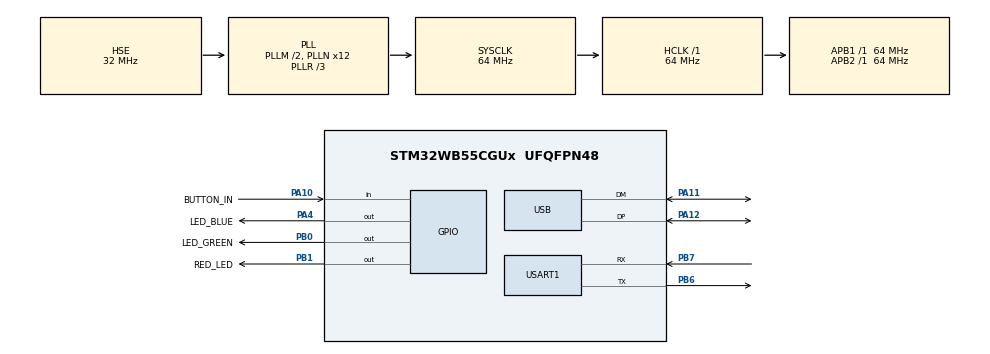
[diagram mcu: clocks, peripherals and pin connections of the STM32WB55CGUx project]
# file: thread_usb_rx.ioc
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Dma.Request0=USART1_RX
Dma.Request1=USART1_TX
Dma.USART1_RX.0.Direction=DMA_PERIPH_TO_MEMORY
Dma.USART1_RX.0.EventEnable=DISABLE
Dma.USART1_RX.0.Instance=DMA1_Channel1
Dma.USART1_RX.0.MemDataAlignment=DMA_MDATAALIGN_BYTE
Dma.USART1_RX.0.MemInc=DMA_MINC_ENABLE
Dma.USART1_RX.0.Mode=DMA_NORMAL
Dma.USART1_RX.0.PeriphDataAlignment=DMA_PDATAALIGN_BYTE
Dma.USART1_RX.0.PeriphInc=DMA_PINC_DISABLE
Dma.USART1_RX.0.Polarity=HAL_DMAMUX_REQ_GEN_RISING
Dma.USART1_RX.0.Priority=DMA_PRIORITY_LOW
Dma.USART1_RX.0.RequestNumber=1
Dma.USART1_RX.0.SignalID=NONE
Dma.USART1_RX.0.SyncEnable=DISABLE
Dma.USART1_RX.0.SyncPolarity=HAL_DMAMUX_SYNC_NO_EVENT
Dma.USART1_RX.0.SyncRequestNumber=1
Dma.USART1_RX.0.SyncSignalID=NONE
Dma.USART1_TX.1.Direction=DMA_MEMORY_TO_PERIPH
Dma.USART1_TX.1.EventEnable=DISABLE
Dma.USART1_TX.1.Instance=DMA1_Channel2
Dma.USART1_TX.1.MemDataAlignment=DMA_MDATAALIGN_BYTE
Dma.USART1_TX.1.MemInc=DMA_MINC_ENABLE
Dma.USART1_TX.1.Mode=DMA_NORMAL
Dma.USART1_TX.1.PeriphDataAlignment=DMA_PDATAALIGN_BYTE
Dma.USART1_TX.1.PeriphInc=DMA_PINC_DISABLE
Dma.USART1_TX.1.Polarity=HAL_DMAMUX_REQ_GEN_RISING
Dma.USART1_TX.1.Priority=DMA_PRIORITY_LOW
Dma.USART1_TX.1.RequestNumber=1
Dma.USART1_TX.1.SignalID=NONE
Dma.USART1_TX.1.SyncEnable=DISABLE
Dma.USART1_TX.1.SyncPolarity=HAL_DMAMUX_SYNC_NO_EVENT
Dma.USART1_TX.1.SyncRequestNumber=1
Dma.USART1_TX.1.SyncSignalID=NONE
Mcu.Family=STM32WB
Mcu.Name=STM32WB55CGUx
Mcu.Package=UFQFPN48
NVIC.DMA1_Channel1_IRQn=true\:0\:0\:false\:false\:true\:false\:true\:true
NVIC.DMA1_Channel2_IRQn=true\:0\:0\:false\:false\:true\:false\:true\:true
NVIC.HSEM_IRQn=true\:0\:0\:false\:false\:true\:false\:true\:true
NVIC.IPCC_C1_RX_IRQn=true\:0\:0\:false\:false\:true\:true\:true\:true
NVIC.IPCC_C1_TX_IRQn=true\:0\:0\:false\:false\:true\:true\:true\:true
NVIC.PriorityGroup=NVIC_PRIORITYGROUP_4
NVIC.USART1_IRQn=true\:0\:0\:false\:false\:true\:true\:true\:true
NVIC.USB_HP_IRQn=true\:0\:0\:false\:false\:true\:true\:true\:true
NVIC.USB_LP_IRQn=true\:0\:0\:false\:false\:true\:true\:true\:true
OSC_IN.Mode=HSE-External-Oscillator
OSC_IN.Signal=RCC_OSC_IN
OSC_OUT.Mode=HSE-External-Oscillator
OSC_OUT.Signal=RCC_OSC_OUT
PA10.GPIO_Label=BUTTON_IN
PA10.Signal=GPIO_Input
PA11.Mode=Device
PA11.Signal=USB_DM
PA12.Mode=Device
PA12.Signal=USB_DP
PA13.Mode=Serial_Wire
PA13.Signal=SYS_JTMS-SWDIO
PA14.Mode=Serial_Wire
PA14.Signal=SYS_JTCK-SWCLK
PA4.GPIO_Label=LED_BLUE
PA4.Signal=GPIO_Output
PB0.GPIO_Label=LED_GREEN
PB0.Signal=GPIO_Output
PB1.GPIO_Label=RED_LED
PB1.Signal=GPIO_Output
PB6.Mode=Asynchronous
PB6.Signal=USART1_TX
PB7.Mode=Asynchronous
PB7.Signal=USART1_RX
PC14-OSC32_IN.Mode=LSE-External-Oscillator
PC14-OSC32_IN.Signal=RCC_OSC32_IN
PC15-OSC32_OUT.Mode=LSE-External-Oscillator
PC15-OSC32_OUT.Signal=RCC_OSC32_OUT
ProjectManager.HeapSize=0x2000
ProjectManager.StackSize=0xA00
ProjectManager.TargetToolchain=STM32CubeIDE
RCC.ADCFreq_Value=64000000
RCC.AHB2CLKDivider=RCC_SYSCLK_DIV2
RCC.AHBFreq_Value=64000000
RCC.APB1Freq_Value=64000000
RCC.APB1TimFreq_Value=64000000
RCC.APB2Freq_Value=64000000
RCC.APB2TimFreq_Value=64000000
RCC.APB3Freq_Value=16000000
RCC.CK48CLockSelection=RCC_USBCLKSOURCE_PLL
RCC.CortexFreq_Value=64000000
RCC.HCLKFreq_Value=64000000
RCC.HSE_VALUE=32000000
RCC.HSI48_VALUE=48000000
RCC.HSI_VALUE=16000000
RCC.PLLM=RCC_PLLM_DIV2
RCC.PLLN=12
RCC.PLLQ=RCC_PLLQ_DIV4
RCC.PLLR=RCC_PLLR_DIV3
RCC.PLLSourceVirtual=RCC_PLLSOURCE_HSE
RCC.RTCClockSelection=RCC_RTCCLKSOURCE_LSE
RCC.SYSCLKFreq_VALUE=64000000
RCC.SYSCLKSource=RCC_SYSCLKSOURCE_PLLCLK
RCC.USBFreq_Value=48000000
RCC.VCOOutputFreq_Value=192000000
RF1.Mode=RF1_Activate
RF1.Signal=RF_RF1
STM32_WPAN.CFG_CLI_UART=hw_uart1
STM32_WPAN.CFG_HW_USART1_ENABLED=1
USART1.VirtualMode-Asynchronous=VM_ASYNC
USB_DEVICE.CLASS_NAME_FS=CDC
USB_DEVICE.VirtualMode=Cdc
USB_DEVICE.VirtualModeFS=Cdc_FS
VP_HSEM_VS_HSEM.Mode=HSEM_Activate
VP_IPCC_VS_IPCC.Mode=IPCC_Activate
VP_RTC_VS_RTC_Activate.Mode=RTC_Enabled
VP_SEQUENCER_VS_SEQUENCER.Mode=SEQUENCER_Enabled
VP_STM32_WPAN_VS_THREAD.Mode=STM32_WPAN_Enabled
VP_TINY_LPM_VS_TINY_LPM.Mode=TINY_LPM_Enabled
VP_USB_DEVICE_VS_USB_DEVICE_CDC_FS.Mode=CDC_FS
board=custom

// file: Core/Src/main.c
/* USER CODE BEGIN Header */
/**
  ******************************************************************************
  * @file           : main.c
  * @brief          : Main program body
  ******************************************************************************
  * @attention
  *
  * Copyright (c) 2022 STMicroelectronics.
  * All rights reserved.
  *
  * This software is licensed under terms that can be found in the LICENSE file
  * in the root directory of this software component.
  * If no LICENSE file comes with this software, it is provided AS-IS.
  *
  ******************************************************************************
  */
/* USER CODE END Header */
#include "main.h"
#include "dma.h"
#include "ipcc.h"
#include "rf.h"
#include "rtc.h"
#include "usart.h"
#include "usb_device.h"
#include "gpio.h"

void SystemClock_Config(void);
void PeriphCommonClock_Config(void);

/* USER CODE BEGIN 0 */

#define PUTCHAR_PROTOTYPE int __io_putchar(int ch)

PUTCHAR_PROTOTYPE
{
  /* Place your implementation of fputc here */
  /* e.g. write a character to the USART1 and Loop until the end of transmission */
 // HAL_UART_Transmit(&huart1, (uint8_t *)&ch, 1, 0xFFFF);
	while(CDC_Transmit_FS((uint8_t *)&ch, 1) == 1);

  return ch;
}

/*
#define LED_BLUE_Pin GPIO_PIN_4
#define LED_BLUE_GPIO_Port GPIOA
#define LED_GREEN_Pin GPIO_PIN_0
#define LED_GREEN_GPIO_Port GPIOB
#define RED_LED_Pin GPIO_PIN_1
#define RED_LED_GPIO_Port GPIOB
#define BUTTON_IN_Pin GPIO_PIN_10
#define BUTTON_IN_GPIO_Port GPIOA
 */

/* USER CODE END 0 */

int main(void)
{

  /* MCU Configuration--------------------------------------------------------*/

  /* Reset of all peripherals, Initializes the Flash interface and the Systick. */
  HAL_Init();
  /* Config code for STM32_WPAN (HSE Tuning must be done before system clock configuration) */
  MX_APPE_Config();

  /* Configure the system clock */
  SystemClock_Config();

/* Configure the peripherals common clocks */
  PeriphCommonClock_Config();

  /* IPCC initialisation */
   MX_IPCC_Init();

  /* Initialize all configured peripherals */
  MX_GPIO_Init();
  MX_DMA_Init();
  MX_RTC_Init();
  MX_USART1_UART_Init();
  MX_RF_Init();
  MX_USB_Device_Init();
  /* USER CODE BEGIN 2 */

  char buf[256] = "Hello world\n";

  /* USER CODE END 2 */

  /* Init code for STM32_WPAN */
  MX_APPE_Init();

  /* Infinite loop */
  /* USER CODE BEGIN WHILE */
  while (1)
  {
	  /*
	  HAL_GPIO_WritePin(LED_GREEN_GPIO_Port, LED_GREEN_Pin, 0);
	  HAL_Delay(100);
	  HAL_GPIO_WritePin(LED_GREEN_GPIO_Port, LED_GREEN_Pin, 1);
	  HAL_Delay(100);
*/
	 // CDC_Transmit_FS(buf, strlen(buf));

    /* USER CODE END WHILE */
    MX_APPE_Process();

  }
}

void SystemClock_Config(void)
{
  RCC_OscInitTypeDef RCC_OscInitStruct = {0};
  RCC_ClkInitTypeDef RCC_ClkInitStruct = {0};

  /** Configure LSE Drive Capability
  */
  HAL_PWR_EnableBkUpAccess();
  __HAL_RCC_LSEDRIVE_CONFIG(RCC_LSEDRIVE_LOW);

  /** Configure the main internal regulator output voltage
  */
  __HAL_PWR_VOLTAGESCALING_CONFIG(PWR_REGULATOR_VOLTAGE_SCALE1);

  /** Initializes the RCC Oscillators according to the specified parameters
  * in the RCC_OscInitTypeDef structure.
  */
  RCC_OscInitStruct.OscillatorType = RCC_OSCILLATORTYPE_HSI|RCC_OSCILLATORTYPE_HSE
                              |RCC_OSCILLATORTYPE_LSE;
  RCC_OscInitStruct.HSEState = RCC_HSE_ON;
  RCC_OscInitStruct.LSEState = RCC_LSE_ON;
  RCC_OscInitStruct.HSIState = RCC_HSI_ON;
  RCC_OscInitStruct.HSICalibrationValue = RCC_HSICALIBRATION_DEFAULT;
  RCC_OscInitStruct.PLL.PLLState = RCC_PLL_ON;
  RCC_OscInitStruct.PLL.PLLSource = RCC_PLLSOURCE_HSE;
  RCC_OscInitStruct.PLL.PLLM = RCC_PLLM_DIV2;
  RCC_OscInitStruct.PLL.PLLN = 12;
  RCC_OscInitStruct.PLL.PLLP = RCC_PLLP_DIV2;
  RCC_OscInitStruct.PLL.PLLR = RCC_PLLR_DIV3;
  RCC_OscInitStruct.PLL.PLLQ = RCC_PLLQ_DIV4;
  if (HAL_RCC_OscConfig(&RCC_OscInitStruct) != HAL_OK)
  {
    Error_Handler();
  }

  /** Configure the SYSCLKSource, HCLK, PCLK1 and PCLK2 clocks dividers
  */
  RCC_ClkInitStruct.ClockType = RCC_CLOCKTYPE_HCLK4|RCC_CLOCKTYPE_HCLK2
                              |RCC_CLOCKTYPE_HCLK|RCC_CLOCKTYPE_SYSCLK
                              |RCC_CLOCKTYPE_PCLK1|RCC_CLOCKTYPE_PCLK2;
  RCC_ClkInitStruct.SYSCLKSource = RCC_SYSCLKSOURCE_PLLCLK;
  RCC_ClkInitStruct.AHBCLKDivider = RCC_SYSCLK_DIV1;
  RCC_ClkInitStruct.APB1CLKDivider = RCC_HCLK_DIV1;
  RCC_ClkInitStruct.APB2CLKDivider = RCC_HCLK_DIV1;
  RCC_ClkInitStruct.AHBCLK2Divider = RCC_SYSCLK_DIV2;
  RCC_ClkInitStruct.AHBCLK4Divider = RCC_SYSCLK_DIV1;

  if (HAL_RCC_ClockConfig(&RCC_ClkInitStruct, FLASH_LATENCY_3) != HAL_OK)
  {
    Error_Handler();
  }
}

void PeriphCommonClock_Config(void)
{
  RCC_PeriphCLKInitTypeDef PeriphClkInitStruct = {0};

  /** Initializes the peripherals clock
  */
  PeriphClkInitStruct.PeriphClockSelection = RCC_PERIPHCLK_SMPS|RCC_PERIPHCLK_RFWAKEUP;
  PeriphClkInitStruct.RFWakeUpClockSelection = RCC_RFWKPCLKSOURCE_HSE_DIV1024;
  PeriphClkInitStruct.SmpsClockSelection = RCC_SMPSCLKSOURCE_HSI;
  PeriphClkInitStruct.SmpsDivSelection = RCC_SMPSCLKDIV_RANGE1;

  if (HAL_RCCEx_PeriphCLKConfig(&PeriphClkInitStruct) != HAL_OK)
  {
    Error_Handler();
  }
  /* USER CODE BEGIN Smps */

  LL_HSEM_1StepLock( HSEM, 5 );  //add this to prevent thread stack usb clock disable!!!!

   // LL_RCC_HSI48_Enable();

   // while(!LL_RCC_HSI48_IsReady());

      /* Select HSI48 as USB clock source */
     // PeriphClkInitStruct.PeriphClockSelection = RCC_PERIPHCLK_USB;
      //PeriphClkInitStruct.UsbClockSelection = RCC_USBCLKSOURCE_HSI48;
      //HAL_RCCEx_PeriphCLKConfig(&PeriphClkInitStruct);

  /* USER CODE END Smps */
}

void Error_Handler(void)
{
  __disable_irq();
  while (1)
  {
  }
}
